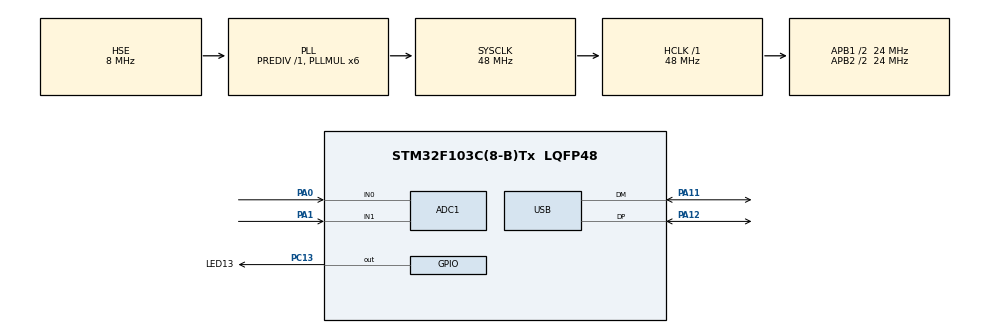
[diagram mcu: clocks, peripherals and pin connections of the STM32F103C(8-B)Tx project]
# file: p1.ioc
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ADC1.Channel-0\#ChannelRegularConversion=ADC_CHANNEL_0
ADC1.Channel-1\#ChannelRegularConversion=ADC_CHANNEL_1
ADC1.NbrOfConversion=2
ADC1.NbrOfConversionFlag=1
ADC1.Rank-0\#ChannelRegularConversion=1
ADC1.Rank-1\#ChannelRegularConversion=2
ADC1.SamplingTime-0\#ChannelRegularConversion=ADC_SAMPLETIME_7CYCLES_5
ADC1.SamplingTime-1\#ChannelRegularConversion=ADC_SAMPLETIME_7CYCLES_5
ADC1.master=1
Dma.ADC1.0.Direction=DMA_PERIPH_TO_MEMORY
Dma.ADC1.0.Instance=DMA1_Channel1
Dma.ADC1.0.MemDataAlignment=DMA_MDATAALIGN_HALFWORD
Dma.ADC1.0.MemInc=DMA_MINC_ENABLE
Dma.ADC1.0.Mode=DMA_NORMAL
Dma.ADC1.0.PeriphDataAlignment=DMA_PDATAALIGN_HALFWORD
Dma.ADC1.0.PeriphInc=DMA_PINC_DISABLE
Dma.ADC1.0.Priority=DMA_PRIORITY_LOW
Dma.Request0=ADC1
Mcu.Family=STM32F1
Mcu.Name=STM32F103C(8-B)Tx
Mcu.Package=LQFP48
NVIC.DMA1_Channel1_IRQn=true\:0\:0\:false\:false\:true\:false\:true
NVIC.PriorityGroup=NVIC_PRIORITYGROUP_4
NVIC.TIM2_IRQn=true\:0\:0\:false\:false\:true\:true\:true
NVIC.USB_LP_CAN1_RX0_IRQn=true\:0\:0\:false\:false\:true\:false\:true
PA0-WKUP.Signal=ADCx_IN0
PA1.Signal=ADCx_IN1
PA11.Mode=Device
PA11.Signal=USB_DM
PA12.Mode=Device
PA12.Signal=USB_DP
PC13-TAMPER-RTC.GPIO_Label=LED13
PC13-TAMPER-RTC.Signal=GPIO_Output
PD0-OSC_IN.Mode=HSE-External-Oscillator
PD0-OSC_IN.Signal=RCC_OSC_IN
PD1-OSC_OUT.Mode=HSE-External-Oscillator
PD1-OSC_OUT.Signal=RCC_OSC_OUT
ProjectManager.HeapSize=0x200
ProjectManager.StackSize=0x400
ProjectManager.TargetToolchain=SW4STM32
RCC.AHBFreq_Value=48000000
RCC.APB1CLKDivider=RCC_HCLK_DIV2
RCC.APB1Freq_Value=24000000
RCC.APB1TimFreq_Value=48000000
RCC.APB2CLKDivider=RCC_HCLK_DIV2
RCC.APB2Freq_Value=24000000
RCC.APB2TimFreq_Value=48000000
RCC.HCLKFreq_Value=48000000
RCC.PLLMUL=RCC_PLL_MUL6
RCC.PLLSourceVirtual=RCC_PLLSOURCE_HSE
RCC.SYSCLKFreq_VALUE=48000000
RCC.SYSCLKSource=RCC_SYSCLKSOURCE_PLLCLK
RCC.USBFreq_Value=48000000
SH.ADCx_IN0.0=ADC1_IN0,IN0
SH.ADCx_IN1.0=ADC1_IN1,IN1
TIM2.Period=999
TIM2.Prescaler=479
USB_DEVICE.CLASS_NAME_FS=CUSTOM_HID
USB_DEVICE.USBD_CUSTOM_HID_REPORT_DESC_SIZE=44
USB_DEVICE.VirtualMode=CustomHid
USB_DEVICE.VirtualModeFS=Custom_Hid_FS
VP_SYS_VS_ND.Mode=No_Debug
VP_TIM2_VS_ClockSourceINT.Mode=Internal
VP_USB_DEVICE_VS_USB_DEVICE_CUSTOM_HID_FS.Mode=CUSTOM_HID_FS
board=custom

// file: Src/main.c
/* USER CODE BEGIN Header */
/**
  ******************************************************************************
  * @file           : main.c
  * @brief          : Main program body
  ******************************************************************************
  * @attention
  *
  * <h2><center>&copy; Copyright (c) 2020 STMicroelectronics.
  * All rights reserved.</center></h2>
  *
  * This software component is licensed by ST under BSD 3-Clause license,
  * the "License"; You may not use this file except in compliance with the
  * License. You may obtain a copy of the License at:
  *                        opensource.org/licenses/BSD-3-Clause
  *
  ******************************************************************************
  */
/* USER CODE END Header */

#include "main.h"
#include "usb_device.h"

ADC_HandleTypeDef hadc1;
DMA_HandleTypeDef hdma_adc1;

TIM_HandleTypeDef htim2;

void SystemClock_Config(void);
static void MX_GPIO_Init(void);
static void MX_TIM2_Init(void);
static void MX_DMA_Init(void);
static void MX_ADC1_Init(void);

int main(void)
{

  /* MCU Configuration--------------------------------------------------------*/

  /* Reset of all peripherals, Initializes the Flash interface and the Systick. */
  HAL_Init();

  /* Configure the system clock */
  SystemClock_Config();

  /* Initialize all configured peripherals */
  MX_GPIO_Init();
  MX_TIM2_Init();
  MX_USB_DEVICE_Init();
  MX_DMA_Init();
  MX_ADC1_Init();
  /* USER CODE BEGIN 2 */

  HAL_ADCEx_Calibration_Start(&hadc1);
  HAL_TIM_Base_Start_IT(&htim2);
  /* USER CODE END 2 */

  /* Infinite loop */
  /* USER CODE BEGIN WHILE */

  while (1)
  {
      /*HAL_Delay(500);
      if(btn_stat==0) {
          dataToSend[9] = 1000 & 0xFF;
          dataToSend[10] = 1000 >> 8;
      } else if(btn_stat==1) {
          dataToSend[9] = 2000 & 0xFF;
          dataToSend[10] = 2000 >> 8;
      } else if(btn_stat==2) {
          dataToSend[9] = 3000 & 0xFF;
          dataToSend[10] = 3000 >> 8;
      } else if(btn_stat==3) {
          dataToSend[9] = 4000 & 0xFF;
          dataToSend[10] = 4000 >> 8;
      }

      USBD_CUSTOM_HID_SendReport(&hUsbDeviceFS, dataToSend, 15);

      btn_stat++;

      if(btn_stat>3) btn_stat=0;*/
    /* USER CODE END WHILE */

  }
}

void SystemClock_Config(void)
{
  RCC_OscInitTypeDef RCC_OscInitStruct = {0};
  RCC_ClkInitTypeDef RCC_ClkInitStruct = {0};
  RCC_PeriphCLKInitTypeDef PeriphClkInit = {0};

  /** Initializes the CPU, AHB and APB busses clocks
  */
  RCC_OscInitStruct.OscillatorType = RCC_OSCILLATORTYPE_HSE;
  RCC_OscInitStruct.HSEState = RCC_HSE_ON;
  RCC_OscInitStruct.HSEPredivValue = RCC_HSE_PREDIV_DIV1;
  RCC_OscInitStruct.HSIState = RCC_HSI_ON;
  RCC_OscInitStruct.PLL.PLLState = RCC_PLL_ON;
  RCC_OscInitStruct.PLL.PLLSource = RCC_PLLSOURCE_HSE;
  RCC_OscInitStruct.PLL.PLLMUL = RCC_PLL_MUL6;
  if (HAL_RCC_OscConfig(&RCC_OscInitStruct) != HAL_OK)
  {
    Error_Handler();
  }
  /** Initializes the CPU, AHB and APB busses clocks
  */
  RCC_ClkInitStruct.ClockType = RCC_CLOCKTYPE_HCLK|RCC_CLOCKTYPE_SYSCLK
                              |RCC_CLOCKTYPE_PCLK1|RCC_CLOCKTYPE_PCLK2;
  RCC_ClkInitStruct.SYSCLKSource = RCC_SYSCLKSOURCE_PLLCLK;
  RCC_ClkInitStruct.AHBCLKDivider = RCC_SYSCLK_DIV1;
  RCC_ClkInitStruct.APB1CLKDivider = RCC_HCLK_DIV2;
  RCC_ClkInitStruct.APB2CLKDivider = RCC_HCLK_DIV2;

  if (HAL_RCC_ClockConfig(&RCC_ClkInitStruct, FLASH_LATENCY_1) != HAL_OK)
  {
    Error_Handler();
  }
  PeriphClkInit.PeriphClockSelection = RCC_PERIPHCLK_ADC|RCC_PERIPHCLK_USB;
  PeriphClkInit.AdcClockSelection = RCC_ADCPCLK2_DIV2;
  PeriphClkInit.UsbClockSelection = RCC_USBCLKSOURCE_PLL;
  if (HAL_RCCEx_PeriphCLKConfig(&PeriphClkInit) != HAL_OK)
  {
    Error_Handler();
  }
}

static void MX_ADC1_Init(void)
{

  ADC_ChannelConfTypeDef sConfig = {0};

  /** Common config
  */
  hadc1.Instance = ADC1;
  hadc1.Init.ScanConvMode = ADC_SCAN_ENABLE;
  hadc1.Init.ContinuousConvMode = DISABLE;
  hadc1.Init.DiscontinuousConvMode = DISABLE;
  hadc1.Init.ExternalTrigConv = ADC_SOFTWARE_START;
  hadc1.Init.DataAlign = ADC_DATAALIGN_RIGHT;
  hadc1.Init.NbrOfConversion = 2;
  if (HAL_ADC_Init(&hadc1) != HAL_OK)
  {
    Error_Handler();
  }
  /** Configure Regular Channel
  */
  sConfig.Channel = ADC_CHANNEL_0;
  sConfig.Rank = ADC_REGULAR_RANK_1;
  sConfig.SamplingTime = ADC_SAMPLETIME_7CYCLES_5;
  if (HAL_ADC_ConfigChannel(&hadc1, &sConfig) != HAL_OK)
  {
    Error_Handler();
  }
  /** Configure Regular Channel
  */
  sConfig.Channel = ADC_CHANNEL_1;
  sConfig.Rank = ADC_REGULAR_RANK_2;
  if (HAL_ADC_ConfigChannel(&hadc1, &sConfig) != HAL_OK)
  {
    Error_Handler();
  }

}

static void MX_TIM2_Init(void)
{

  TIM_ClockConfigTypeDef sClockSourceConfig = {0};
  TIM_MasterConfigTypeDef sMasterConfig = {0};

  htim2.Instance = TIM2;
  htim2.Init.Prescaler = 479;
  htim2.Init.CounterMode = TIM_COUNTERMODE_UP;
  htim2.Init.Period = 999;
  htim2.Init.ClockDivision = TIM_CLOCKDIVISION_DIV1;
  htim2.Init.AutoReloadPreload = TIM_AUTORELOAD_PRELOAD_DISABLE;
  if (HAL_TIM_Base_Init(&htim2) != HAL_OK)
  {
    Error_Handler();
  }
  sClockSourceConfig.ClockSource = TIM_CLOCKSOURCE_INTERNAL;
  if (HAL_TIM_ConfigClockSource(&htim2, &sClockSourceConfig) != HAL_OK)
  {
    Error_Handler();
  }
  sMasterConfig.MasterOutputTrigger = TIM_TRGO_RESET;
  sMasterConfig.MasterSlaveMode = TIM_MASTERSLAVEMODE_DISABLE;
  if (HAL_TIMEx_MasterConfigSynchronization(&htim2, &sMasterConfig) != HAL_OK)
  {
    Error_Handler();
  }

}

static void MX_DMA_Init(void)
{

  /* DMA controller clock enable */
  __HAL_RCC_DMA1_CLK_ENABLE();

  /* DMA interrupt init */
  /* DMA1_Channel1_IRQn interrupt configuration */
  HAL_NVIC_SetPriority(DMA1_Channel1_IRQn, 0, 0);
  HAL_NVIC_EnableIRQ(DMA1_Channel1_IRQn);

}

static void MX_GPIO_Init(void)
{
  GPIO_InitTypeDef GPIO_InitStruct = {0};

  /* GPIO Ports Clock Enable */
  __HAL_RCC_GPIOC_CLK_ENABLE();
  __HAL_RCC_GPIOD_CLK_ENABLE();
  __HAL_RCC_GPIOA_CLK_ENABLE();

  /*Configure GPIO pin Output Level */
  HAL_GPIO_WritePin(LED13_GPIO_Port, LED13_Pin, GPIO_PIN_RESET);

  /*Configure GPIO pin : LED13_Pin */
  GPIO_InitStruct.Pin = LED13_Pin;
  GPIO_InitStruct.Mode = GPIO_MODE_OUTPUT_PP;
  GPIO_InitStruct.Pull = GPIO_NOPULL;
  GPIO_InitStruct.Speed = GPIO_SPEED_FREQ_LOW;
  HAL_GPIO_Init(LED13_GPIO_Port, &GPIO_InitStruct);

}

void Error_Handler(void)
{
}

/************************ (C) COPYRIGHT STMicroelectronics *****END OF FILE****/
